# WKUP_WKUP_SEC_MMR0_CFG0 register map
Vendor: Texas Instruments
Peripheral module from a debugger description file (folder am62P).
Registers are 32-bit, read-write, reset 0x0 unless marked. A register's access mark holds for its fields unless they carry their own. Offsets are as the file gives them; lines under a group give offsets from that group; [hi:lo] are bit positions; {n}, {i} and the like mark numbered series; 'fields as' and 'values as' point back to an identical list; <NAME> marks a mode.

## WKUP_WKUP_SEC_MMR0_CFG0
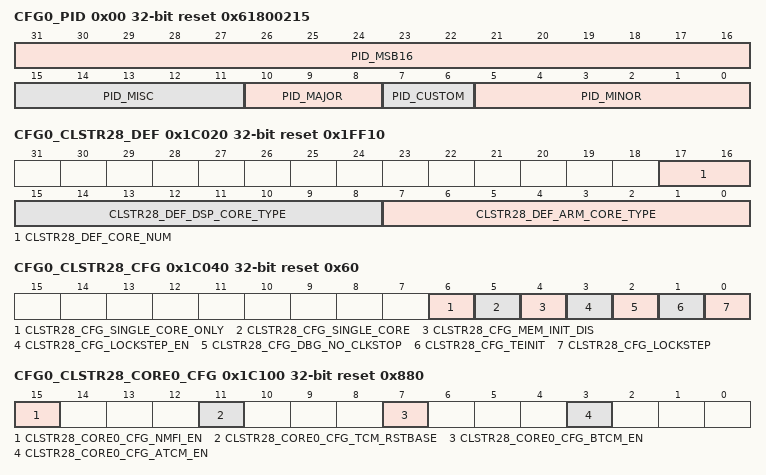
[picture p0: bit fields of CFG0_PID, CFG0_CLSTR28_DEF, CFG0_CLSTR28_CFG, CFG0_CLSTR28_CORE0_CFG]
0x00 CFG0_PID ro reset 0x61800215
  [31:16] PID_MSB16, [15:11] PID_MISC, [10:8] PID_MAJOR, [7:6] PID_CUSTOM, [5:0] PID_MINOR
0x1C020 CFG0_CLSTR28_DEF ro reset 0x1FF10
  [17:16] CLSTR28_DEF_CORE_NUM — Number of cores in cluster 001 - Single Core 010 - Dual Core
  [15:8] CLSTR28_DEF_DSP_CORE_TYPE — DSP core type configuration Field values (others are reserved): 8'h00 - C7x 8'h01 - C6x 8'hFF - Not DSP
  [7:0] CLSTR28_DEF_ARM_CORE_TYPE — ARM core type configuration Field values (others are reserved): 8'h00 - A53 8'h01 - A57 8'h10 - R5 8'h11 - M4F 8'hFF - Not ARM
0x1C040 CFG0_CLSTR28_CFG access per field reset 0x60
  [6] CLSTR28_CFG_SINGLE_CORE_ONLY ro — Single / Dual CPU Mode Supported: 0 = Both Dual and Single Core are supported 1 = Only Single Core Mode is Supported
  [5] CLSTR28_CFG_SINGLE_CORE ro — Single / Dual CPU Mode: 0 = Unsupported on this device 1 = Only CPU0 is active.
  [4] CLSTR28_CFG_MEM_INIT_DIS rw — Deactivates SRAM initialization (TCM, Cache Tags, etc) at reset Initialization must be performed for proper initial ECC initialization. The mem_init_dis value must be selected prior to R5 reset assertion. 1'b0 - Perform memory initialization 1'b1 - Deactivate memory initialization
  [3] CLSTR28_CFG_LOCKSTEP_EN ro — Lockstep Not Supported
  [2] CLSTR28_CFG_DBG_NO_CLKSTOP rw — CPU clockstop behavior 0 - CPU clocks stopped and nCLOCKSTOPPED asserted in standby mode 1 - CPU clocks not stopped in standby mode
  [1] CLSTR28_CFG_TEINIT rw — Exception handling state at reset: 0 - ARM mode 1 - Thumb mode CAUTION: This bit must not be modified while R5F CPU is released from reset.
  [0] CLSTR28_CFG_LOCKSTEP ro — Lockstep Not Supported
0x1C080 CFG0_CLSTR28_PMCTRL access not given reset not defined
0x1C090 CFG0_CLSTR28_PMSTAT access not given reset not defined
0x1C100 CFG0_CLSTR28_CORE0_CFG reset 0x880
  [15] CLSTR28_CORE0_CFG_NMFI_EN — Activate Core0 Non-Maskable Fast Interrupts CAUTION: This bit must not be modified while R5F CPU is released from reset.
  [11] CLSTR28_CORE0_CFG_TCM_RSTBASE — Core0 A/BTCM Reset Base Address Indicator 0 - BTCM located at address 0x0 1 - ATCM located at address 0x0 CAUTION: This bit must not be modified while R5F CPU is released from reset.
  [7] CLSTR28_CORE0_CFG_BTCM_EN — Activate Core0 BTCM RAM at reset CAUTION: This bit must not be modified while R5F CPU is released from reset.
  [3] CLSTR28_CORE0_CFG_ATCM_EN — Activate Core0 ATCM RAM at reset CAUTION: This bit must not be modified while R5F CPU is released from reset.
0x1C110 CFG0_CLSTR28_CORE0_BOOTVECT_LO reset 0x200
  [31:7] CLSTR28_CORE0_BOOTVECT_LO_VECT_ADDR — Specifies the lower 25 bits of the 41-bit vector address corresponding to Vector Table address bits[31:7]. Note bits 6:0 of the Vector Table address are always 0.
0x1C114 CFG0_CLSTR28_CORE0_BOOTVECT_HI
  [15:0] CLSTR28_CORE0_BOOTVECT_HI_VECT_ADDR — Specifies the upper 16 bits of the 41-bit vector address corresponding to Vector Table address bits[47:32].
0x1C120 CFG0_CLSTR28_CORE0_PMCTRL
  [0] CLSTR28_CORE0_PMCTRL_CORE_HALT — Halt Core0 Field values (others are reserved): 1'b0 - CPU is held waiting to begin execution after reset is released 1'b1 - CPU is released to execute
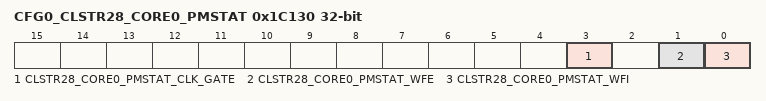
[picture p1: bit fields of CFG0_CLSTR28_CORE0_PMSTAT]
0x1C130 CFG0_CLSTR28_CORE0_PMSTAT ro
  [3] CLSTR28_CORE0_PMSTAT_CLK_GATE — Core0 Clocked stopped due to WFI or WFE state Note: Informaton is only valid when core is out of reset.
  [1] CLSTR28_CORE0_PMSTAT_WFE — Core0 WFE When 0, indicates that Core0 is in the WFE state Note: Informaton is only valid when core is out of reset.
  [0] CLSTR28_CORE0_PMSTAT_WFI — Core0 WFI When 0, indicates that Core0 is in the WFI state Note: Informaton is only valid when core is out of reset.
